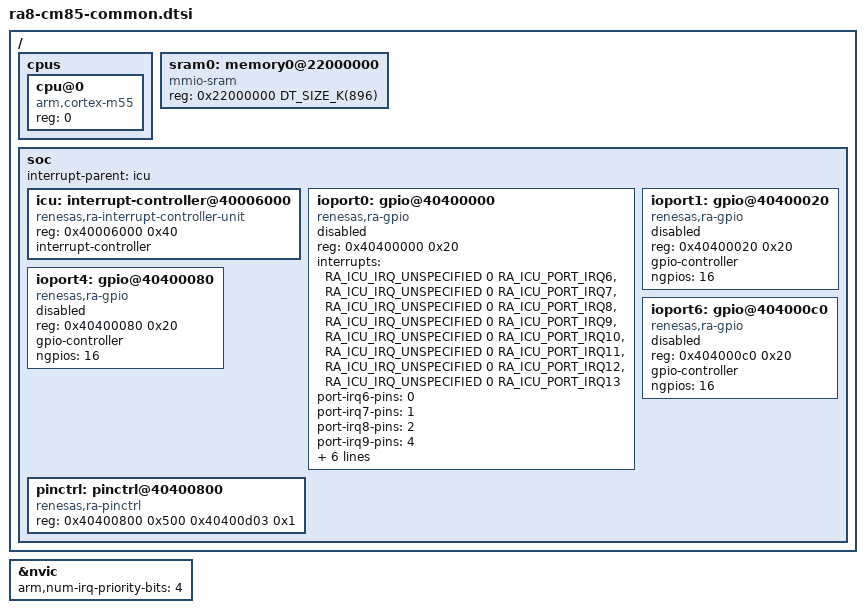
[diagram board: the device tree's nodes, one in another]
#include <mem.h>
#include <freq.h>
#include <arm/armv8-m.dtsi>
#include <zephyr/dt-bindings/interrupt-controller/renesas-ra-icu.h>

/ {
	cpus {
		#address-cells = <1>;
		#size-cells = <0>;

		cpu@0 {
			device_type = "cpu";
			// Lie
			compatible = "arm,cortex-m55";
			reg = <0>;
		};
	};

	sram0: memory0@22000000 {
		compatible = "mmio-sram";
		reg = <0x22000000 DT_SIZE_K(896)>;
	};

	soc {
		interrupt-parent = <&icu>;
		icu: interrupt-controller@40006000 {
			compatible = "renesas,ra-interrupt-controller-unit";
			reg = <0x40006000 0x40>;
			reg-names = "icu";
			interrupt-controller;
			#interrupt-cells = <3>;
		};

		ioport0: gpio@40400000 {
			compatible = "renesas,ra-gpio";
			reg = <0x40400000 0x20>;

			interrupts = <RA_ICU_IRQ_UNSPECIFIED 0 RA_ICU_PORT_IRQ6>,
				     <RA_ICU_IRQ_UNSPECIFIED 0 RA_ICU_PORT_IRQ7>,
				     <RA_ICU_IRQ_UNSPECIFIED 0 RA_ICU_PORT_IRQ8>,
				     <RA_ICU_IRQ_UNSPECIFIED 0 RA_ICU_PORT_IRQ9>,
				     <RA_ICU_IRQ_UNSPECIFIED 0 RA_ICU_PORT_IRQ10>,
				     <RA_ICU_IRQ_UNSPECIFIED 0 RA_ICU_PORT_IRQ11>,
				     <RA_ICU_IRQ_UNSPECIFIED 0 RA_ICU_PORT_IRQ12>,
				     <RA_ICU_IRQ_UNSPECIFIED 0 RA_ICU_PORT_IRQ13>;

			interrupt-names = "port-irq6", "port-irq7", "port-irq8",
					  "port-irq9", "port-irq10", "port-irq11",
					  "port-irq12" , "port-irq13";

			port-irq6-pins = <0>;
			port-irq7-pins = <1>;
			port-irq8-pins = <2>;
			port-irq9-pins = <4>;
			port-irq10-pins = <5>;
			port-irq11-pins = <6>;
			port-irq12-pins = <8>;
			port-irq13-pins = <9>;

			gpio-controller;
			#gpio-cells = <2>;
			ngpios = <16>;
                        status = "disabled";
                };

		ioport1: gpio@40400020 {
			compatible = "renesas,ra-gpio";
			reg = <0x40400020 0x20>;

			gpio-controller;
			#gpio-cells = <2>;
			ngpios = <16>;
                        status = "disabled";
                };

		ioport4: gpio@40400080 {
			compatible = "renesas,ra-gpio";
			reg = <0x40400080 0x20>;

			gpio-controller;
			#gpio-cells = <2>;
			ngpios = <16>;
                        status = "disabled";
                };

		ioport6: gpio@404000c0 {
			compatible = "renesas,ra-gpio";
			reg = <0x404000c0 0x20>;

			gpio-controller;
			#gpio-cells = <2>;
			ngpios = <16>;
                        status = "disabled";
                };

		pinctrl: pinctrl@40400800 {
			compatible = "renesas,ra-pinctrl";
			reg = <0x40400800 0x500 0x40400d03 0x1>;
			reg-names = "pfs", "pmisc_pwpr";
			status = "okay";
		};
	};
};

&nvic {
	arm,num-irq-priority-bits = <4>;
};
